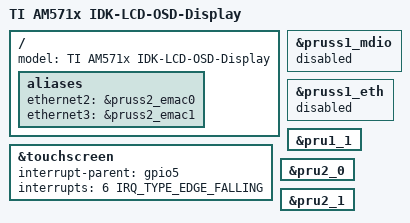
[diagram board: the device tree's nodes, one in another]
/*
 * Copyright (C) 2015 Texas Instruments Incorporated - http://www.ti.com/
 *
 * This program is free software; you can redistribute it and/or modify
 * it under the terms of the GNU General Public License version 2 as
 * published by the Free Software Foundation.
 */

#include "am571x-idk.dts"
#include "am57xx-idk-lcd-osd.dtsi"

/ {
	model = "TI AM571x IDK-LCD-OSD-Display";

	aliases {
		ethernet2 = &pruss2_emac0;
		ethernet3 = &pruss2_emac1;
		/delete-property/ ethernet4;
		/delete-property/ ethernet5;
	};
};

&touchscreen {
	interrupt-parent = <&gpio5>;
	interrupts = <6 IRQ_TYPE_EDGE_FALLING>;
};

&pruss1_mdio {
	status = "disabled";
};

&pruss1_eth {
	status = "disabled";
};

&pru1_1 {
	/delete-property/ ti,pruss-gp-mux-sel;
};

&pru2_0 {
	/delete-property/ ti,pruss-gp-mux-sel;
};

&pru2_1 {
	/delete-property/ ti,pruss-gp-mux-sel;
};
